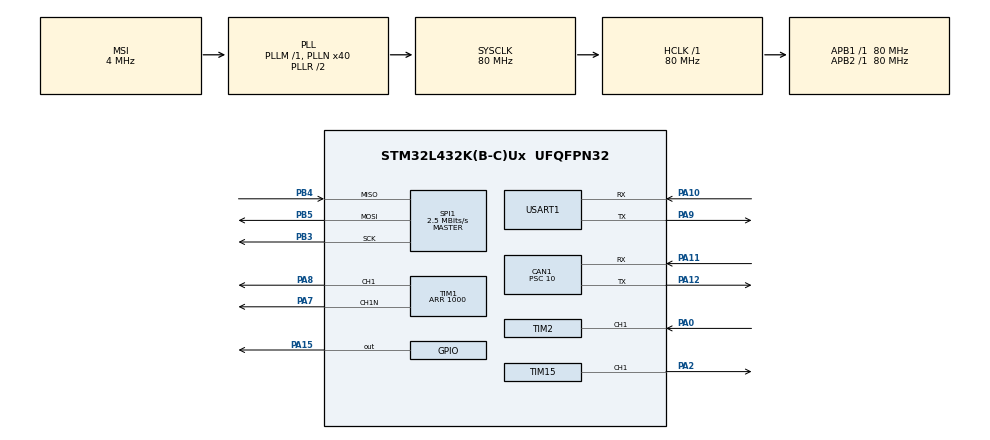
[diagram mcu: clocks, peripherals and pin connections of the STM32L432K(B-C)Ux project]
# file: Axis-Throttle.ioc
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CAN1.BS1=CAN_BS1_7TQ
CAN1.BS2=CAN_BS2_8TQ
CAN1.CalculateBaudRate=500000
CAN1.CalculateTimeBit=2000
CAN1.CalculateTimeQuantum=125.0
CAN1.Prescaler=10
CAN1.SJW=CAN_SJW_2TQ
CAN1.TXFP=ENABLE
Dma.Request0=USART1_RX
Dma.Request1=USART1_TX
Dma.USART1_RX.0.Direction=DMA_PERIPH_TO_MEMORY
Dma.USART1_RX.0.Instance=DMA1_Channel5
Dma.USART1_RX.0.MemDataAlignment=DMA_MDATAALIGN_BYTE
Dma.USART1_RX.0.MemInc=DMA_MINC_ENABLE
Dma.USART1_RX.0.Mode=DMA_NORMAL
Dma.USART1_RX.0.PeriphDataAlignment=DMA_PDATAALIGN_BYTE
Dma.USART1_RX.0.PeriphInc=DMA_PINC_DISABLE
Dma.USART1_RX.0.Priority=DMA_PRIORITY_LOW
Dma.USART1_TX.1.Direction=DMA_MEMORY_TO_PERIPH
Dma.USART1_TX.1.Instance=DMA1_Channel4
Dma.USART1_TX.1.MemDataAlignment=DMA_MDATAALIGN_BYTE
Dma.USART1_TX.1.MemInc=DMA_MINC_ENABLE
Dma.USART1_TX.1.Mode=DMA_NORMAL
Dma.USART1_TX.1.PeriphDataAlignment=DMA_PDATAALIGN_BYTE
Dma.USART1_TX.1.PeriphInc=DMA_PINC_DISABLE
Dma.USART1_TX.1.Priority=DMA_PRIORITY_LOW
FREERTOS.Tasks01=defaultTask,24,128,StartDefaultTask,Default,NULL,Dynamic,NULL,NULL
FREERTOS.configENABLE_FPU=1
FREERTOS.configGENERATE_RUN_TIME_STATS=1
FREERTOS.configTOTAL_HEAP_SIZE=40000
FREERTOS.configUSE_NEWLIB_REENTRANT=1
FREERTOS.configUSE_STATS_FORMATTING_FUNCTIONS=1
Mcu.Family=STM32L4
Mcu.Name=STM32L432K(B-C)Ux
Mcu.Package=UFQFPN32
NVIC.CAN1_RX0_IRQn=true\:5\:0\:false\:false\:false\:true\:true\:true\:true
NVIC.DMA1_Channel4_IRQn=true\:5\:0\:false\:false\:true\:true\:false\:true\:true
NVIC.DMA1_Channel5_IRQn=true\:5\:0\:false\:false\:true\:true\:false\:true\:true
NVIC.PriorityGroup=NVIC_PRIORITYGROUP_4
NVIC.USART1_IRQn=true\:5\:0\:false\:false\:true\:true\:true\:true\:true
PA0.Signal=S_TIM2_CH1
PA10.Mode=Asynchronous
PA10.Signal=USART1_RX
PA11.GPIO_PuPd=GPIO_PULLUP
PA11.Mode=CAN_Activate
PA11.Signal=CAN1_RX
PA12.Mode=CAN_Activate
PA12.Signal=CAN1_TX
PA13\ (JTMS-SWDIO).Mode=Serial_Wire
PA13\ (JTMS-SWDIO).Signal=SYS_JTMS-SWDIO
PA14\ (JTCK-SWCLK).Mode=Serial_Wire
PA14\ (JTCK-SWCLK).Signal=SYS_JTCK-SWCLK
PA15\ (JTDI).Signal=GPIO_Output
PA2.Signal=S_TIM15_CH1
PA7.Mode=PWM Generation1 CH1 CH1N
PA7.Signal=TIM1_CH1N
PA8.Signal=S_TIM1_CH1
PA9.Mode=Asynchronous
PA9.Signal=USART1_TX
PB3\ (JTDO-TRACESWO).Mode=Full_Duplex_Master
PB3\ (JTDO-TRACESWO).Signal=SPI1_SCK
PB4\ (NJTRST).Mode=Full_Duplex_Master
PB4\ (NJTRST).Signal=SPI1_MISO
PB5.Mode=Full_Duplex_Master
PB5.Signal=SPI1_MOSI
ProjectManager.HeapSize=0x200
ProjectManager.StackSize=0x400
ProjectManager.TargetToolchain=STM32CubeIDE
RCC.ADCFreq_Value=16000000
RCC.AHBFreq_Value=80000000
RCC.APB1Freq_Value=80000000
RCC.APB1TimFreq_Value=80000000
RCC.APB2Freq_Value=80000000
RCC.APB2TimFreq_Value=80000000
RCC.CortexFreq_Value=80000000
RCC.HCLKFreq_Value=80000000
RCC.HSE_VALUE=8000000
RCC.HSI48_VALUE=48000000
RCC.HSI_VALUE=16000000
RCC.LSE_VALUE=32768
RCC.MSI_VALUE=4000000
RCC.PLLN=40
RCC.SYSCLKFreq_VALUE=80000000
RCC.SYSCLKSource=RCC_SYSCLKSOURCE_PLLCLK
RCC.USBFreq_Value=16000000
RCC.VCOOutputFreq_Value=160000000
SH.S_TIM15_CH1.0=TIM15_CH1,PWM Generation1 CH1
SH.S_TIM1_CH1.0=TIM1_CH1,PWM Generation1 CH1 CH1N
SH.S_TIM2_CH1.0=TIM2_CH1,Input_Capture1_from_TI1
SH.S_TIM2_CH1.1=TIM2_CH1,TriggerSource_TI1FP1
SPI1.BaudRatePrescaler=SPI_BAUDRATEPRESCALER_32
SPI1.CLKPhase=SPI_PHASE_2EDGE
SPI1.CLKPolarity=SPI_POLARITY_HIGH
SPI1.CalculateBaudRate=2.5 MBits/s
SPI1.DataSize=SPI_DATASIZE_16BIT
SPI1.Direction=SPI_DIRECTION_2LINES
SPI1.Mode=SPI_MODE_MASTER
SPI1.TIMode=SPI_TIMODE_DISABLE
SPI1.VirtualType=VM_MASTER
TIM1.Channel-PWM\ Generation1\ CH1\ CH1N=TIM_CHANNEL_1
TIM1.Period=1000
TIM15.Channel-PWM\ Generation1\ CH1=TIM_CHANNEL_1
TIM15.Period=40000
TIM15.Prescaler=39
TIM2.Channel-Input_Capture1_from_TI1=TIM_CHANNEL_1
TIM2.Channel-Input_Capture2_from_TI1_63=TIM_CHANNEL_2
TIM2.ICPolarity_CH2=TIM_INPUTCHANNELPOLARITY_FALLING
TIM2.Prescaler=19
USART1.VirtualMode-Asynchronous=VM_ASYNC
VP_FREERTOS_VS_CMSIS_V2.Mode=CMSIS_V2
VP_TIM2_VS_ControllerModeReset.Mode=Reset Mode
VP_TIM2_VS_indirect_ch1.Mode=Input_Capture2_from_TI1_63
board=custom

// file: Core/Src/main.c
/* USER CODE BEGIN Header */
/**
  ******************************************************************************
  * @file           : main.c
  * @brief          : Main program body
  ******************************************************************************
  * @attention
  *
  * Copyright (c) 2024 STMicroelectronics.
  * All rights reserved.
  *
  * This software is licensed under terms that can be found in the LICENSE file
  * in the root directory of this software component.
  * If no LICENSE file comes with this software, it is provided AS-IS.
  *
  ******************************************************************************
  */
/* USER CODE END Header */
#include "main.h"
#include "cmsis_os.h"

/* USER CODE BEGIN Includes */
#include "Tasks/init.h"

/* USER CODE END Includes */

CAN_HandleTypeDef hcan1;

SPI_HandleTypeDef hspi1;

TIM_HandleTypeDef htim1;
TIM_HandleTypeDef htim2;
TIM_HandleTypeDef htim15;

UART_HandleTypeDef huart1;
DMA_HandleTypeDef hdma_usart1_rx;
DMA_HandleTypeDef hdma_usart1_tx;

/* Definitions for defaultTask */
osThreadId_t defaultTaskHandle;
const osThreadAttr_t defaultTask_attributes = {
  .name = "defaultTask",
  .stack_size = 128 * 4,
  .priority = (osPriority_t) osPriorityNormal,
};

void SystemClock_Config(void);
static void MX_GPIO_Init(void);
static void MX_DMA_Init(void);
static void MX_CAN1_Init(void);
static void MX_SPI1_Init(void);
static void MX_TIM1_Init(void);
static void MX_TIM2_Init(void);
static void MX_TIM15_Init(void);
static void MX_USART1_UART_Init(void);
void StartDefaultTask(void *argument);

int main(void)
{

  /* MCU Configuration--------------------------------------------------------*/

  /* Reset of all peripherals, Initializes the Flash interface and the Systick. */
  HAL_Init();

  /* Configure the system clock */
  SystemClock_Config();

  /* Initialize all configured peripherals */
  MX_GPIO_Init();
  MX_DMA_Init();
  MX_CAN1_Init();
  MX_SPI1_Init();
  MX_TIM1_Init();
  MX_TIM2_Init();
  MX_TIM15_Init();
  MX_USART1_UART_Init();

  /* Init scheduler */
  osKernelInitialize();

  /* Create the thread(s) */
  /* creation of defaultTask */
  defaultTaskHandle = osThreadNew(StartDefaultTask, NULL, &defaultTask_attributes);

  /* USER CODE BEGIN RTOS_THREADS */

  init_system();
  /* add threads, ... */
  /* USER CODE END RTOS_THREADS */

  /* Start scheduler */
  osKernelStart();

  /* We should never get here as control is now taken by the scheduler */
  /* Infinite loop */
  while (1)
  {

  }
}

void SystemClock_Config(void)
{
  RCC_OscInitTypeDef RCC_OscInitStruct = {0};
  RCC_ClkInitTypeDef RCC_ClkInitStruct = {0};

  /** Configure the main internal regulator output voltage
  */
  if (HAL_PWREx_ControlVoltageScaling(PWR_REGULATOR_VOLTAGE_SCALE1) != HAL_OK)
  {
    Error_Handler();
  }

  /** Initializes the RCC Oscillators according to the specified parameters
  * in the RCC_OscInitTypeDef structure.
  */
  RCC_OscInitStruct.OscillatorType = RCC_OSCILLATORTYPE_MSI;
  RCC_OscInitStruct.MSIState = RCC_MSI_ON;
  RCC_OscInitStruct.MSICalibrationValue = 0;
  RCC_OscInitStruct.MSIClockRange = RCC_MSIRANGE_6;
  RCC_OscInitStruct.PLL.PLLState = RCC_PLL_ON;
  RCC_OscInitStruct.PLL.PLLSource = RCC_PLLSOURCE_MSI;
  RCC_OscInitStruct.PLL.PLLM = 1;
  RCC_OscInitStruct.PLL.PLLN = 40;
  RCC_OscInitStruct.PLL.PLLP = RCC_PLLP_DIV7;
  RCC_OscInitStruct.PLL.PLLQ = RCC_PLLQ_DIV2;
  RCC_OscInitStruct.PLL.PLLR = RCC_PLLR_DIV2;
  if (HAL_RCC_OscConfig(&RCC_OscInitStruct) != HAL_OK)
  {
    Error_Handler();
  }

  /** Initializes the CPU, AHB and APB buses clocks
  */
  RCC_ClkInitStruct.ClockType = RCC_CLOCKTYPE_HCLK|RCC_CLOCKTYPE_SYSCLK
                              |RCC_CLOCKTYPE_PCLK1|RCC_CLOCKTYPE_PCLK2;
  RCC_ClkInitStruct.SYSCLKSource = RCC_SYSCLKSOURCE_PLLCLK;
  RCC_ClkInitStruct.AHBCLKDivider = RCC_SYSCLK_DIV1;
  RCC_ClkInitStruct.APB1CLKDivider = RCC_HCLK_DIV1;
  RCC_ClkInitStruct.APB2CLKDivider = RCC_HCLK_DIV1;

  if (HAL_RCC_ClockConfig(&RCC_ClkInitStruct, FLASH_LATENCY_4) != HAL_OK)
  {
    Error_Handler();
  }
}

static void MX_CAN1_Init(void)
{

  hcan1.Instance = CAN1;
  hcan1.Init.Prescaler = 10;
  hcan1.Init.Mode = CAN_MODE_NORMAL;
  hcan1.Init.SyncJumpWidth = CAN_SJW_2TQ;
  hcan1.Init.TimeSeg1 = CAN_BS1_7TQ;
  hcan1.Init.TimeSeg2 = CAN_BS2_8TQ;
  hcan1.Init.TimeTriggeredMode = DISABLE;
  hcan1.Init.AutoBusOff = DISABLE;
  hcan1.Init.AutoWakeUp = DISABLE;
  hcan1.Init.AutoRetransmission = DISABLE;
  hcan1.Init.ReceiveFifoLocked = DISABLE;
  hcan1.Init.TransmitFifoPriority = ENABLE;
  if (HAL_CAN_Init(&hcan1) != HAL_OK)
  {
    Error_Handler();
  }

}

static void MX_SPI1_Init(void)
{

  /* SPI1 parameter configuration*/
  hspi1.Instance = SPI1;
  hspi1.Init.Mode = SPI_MODE_MASTER;
  hspi1.Init.Direction = SPI_DIRECTION_2LINES;
  hspi1.Init.DataSize = SPI_DATASIZE_16BIT;
  hspi1.Init.CLKPolarity = SPI_POLARITY_HIGH;
  hspi1.Init.CLKPhase = SPI_PHASE_2EDGE;
  hspi1.Init.NSS = SPI_NSS_SOFT;
  hspi1.Init.BaudRatePrescaler = SPI_BAUDRATEPRESCALER_32;
  hspi1.Init.FirstBit = SPI_FIRSTBIT_MSB;
  hspi1.Init.TIMode = SPI_TIMODE_DISABLE;
  hspi1.Init.CRCCalculation = SPI_CRCCALCULATION_DISABLE;
  hspi1.Init.CRCPolynomial = 7;
  hspi1.Init.CRCLength = SPI_CRC_LENGTH_DATASIZE;
  hspi1.Init.NSSPMode = SPI_NSS_PULSE_DISABLE;
  if (HAL_SPI_Init(&hspi1) != HAL_OK)
  {
    Error_Handler();
  }

}

static void MX_TIM1_Init(void)
{

  TIM_MasterConfigTypeDef sMasterConfig = {0};
  TIM_OC_InitTypeDef sConfigOC = {0};
  TIM_BreakDeadTimeConfigTypeDef sBreakDeadTimeConfig = {0};

  htim1.Instance = TIM1;
  htim1.Init.Prescaler = 0;
  htim1.Init.CounterMode = TIM_COUNTERMODE_UP;
  htim1.Init.Period = 1000;
  htim1.Init.ClockDivision = TIM_CLOCKDIVISION_DIV1;
  htim1.Init.RepetitionCounter = 0;
  htim1.Init.AutoReloadPreload = TIM_AUTORELOAD_PRELOAD_DISABLE;
  if (HAL_TIM_PWM_Init(&htim1) != HAL_OK)
  {
    Error_Handler();
  }
  sMasterConfig.MasterOutputTrigger = TIM_TRGO_RESET;
  sMasterConfig.MasterOutputTrigger2 = TIM_TRGO2_RESET;
  sMasterConfig.MasterSlaveMode = TIM_MASTERSLAVEMODE_DISABLE;
  if (HAL_TIMEx_MasterConfigSynchronization(&htim1, &sMasterConfig) != HAL_OK)
  {
    Error_Handler();
  }
  sConfigOC.OCMode = TIM_OCMODE_PWM1;
  sConfigOC.Pulse = 0;
  sConfigOC.OCPolarity = TIM_OCPOLARITY_HIGH;
  sConfigOC.OCNPolarity = TIM_OCNPOLARITY_HIGH;
  sConfigOC.OCFastMode = TIM_OCFAST_DISABLE;
  sConfigOC.OCIdleState = TIM_OCIDLESTATE_RESET;
  sConfigOC.OCNIdleState = TIM_OCNIDLESTATE_RESET;
  if (HAL_TIM_PWM_ConfigChannel(&htim1, &sConfigOC, TIM_CHANNEL_1) != HAL_OK)
  {
    Error_Handler();
  }
  sBreakDeadTimeConfig.OffStateRunMode = TIM_OSSR_DISABLE;
  sBreakDeadTimeConfig.OffStateIDLEMode = TIM_OSSI_DISABLE;
  sBreakDeadTimeConfig.LockLevel = TIM_LOCKLEVEL_OFF;
  sBreakDeadTimeConfig.DeadTime = 0;
  sBreakDeadTimeConfig.BreakState = TIM_BREAK_DISABLE;
  sBreakDeadTimeConfig.BreakPolarity = TIM_BREAKPOLARITY_HIGH;
  sBreakDeadTimeConfig.BreakFilter = 0;
  sBreakDeadTimeConfig.Break2State = TIM_BREAK2_DISABLE;
  sBreakDeadTimeConfig.Break2Polarity = TIM_BREAK2POLARITY_HIGH;
  sBreakDeadTimeConfig.Break2Filter = 0;
  sBreakDeadTimeConfig.AutomaticOutput = TIM_AUTOMATICOUTPUT_DISABLE;
  if (HAL_TIMEx_ConfigBreakDeadTime(&htim1, &sBreakDeadTimeConfig) != HAL_OK)
  {
    Error_Handler();
  }
  HAL_TIM_MspPostInit(&htim1);

}

static void MX_TIM2_Init(void)
{

  TIM_SlaveConfigTypeDef sSlaveConfig = {0};
  TIM_MasterConfigTypeDef sMasterConfig = {0};
  TIM_IC_InitTypeDef sConfigIC = {0};

  htim2.Instance = TIM2;
  htim2.Init.Prescaler = 19;
  htim2.Init.CounterMode = TIM_COUNTERMODE_UP;
  htim2.Init.Period = 4294967295;
  htim2.Init.ClockDivision = TIM_CLOCKDIVISION_DIV1;
  htim2.Init.AutoReloadPreload = TIM_AUTORELOAD_PRELOAD_DISABLE;
  if (HAL_TIM_Base_Init(&htim2) != HAL_OK)
  {
    Error_Handler();
  }
  if (HAL_TIM_IC_Init(&htim2) != HAL_OK)
  {
    Error_Handler();
  }
  sSlaveConfig.SlaveMode = TIM_SLAVEMODE_RESET;
  sSlaveConfig.InputTrigger = TIM_TS_TI1FP1;
  sSlaveConfig.TriggerPolarity = TIM_INPUTCHANNELPOLARITY_RISING;
  sSlaveConfig.TriggerFilter = 0;
  if (HAL_TIM_SlaveConfigSynchro(&htim2, &sSlaveConfig) != HAL_OK)
  {
    Error_Handler();
  }
  sMasterConfig.MasterOutputTrigger = TIM_TRGO_RESET;
  sMasterConfig.MasterSlaveMode = TIM_MASTERSLAVEMODE_DISABLE;
  if (HAL_TIMEx_MasterConfigSynchronization(&htim2, &sMasterConfig) != HAL_OK)
  {
    Error_Handler();
  }
  sConfigIC.ICPolarity = TIM_INPUTCHANNELPOLARITY_RISING;
  sConfigIC.ICSelection = TIM_ICSELECTION_DIRECTTI;
  sConfigIC.ICPrescaler = TIM_ICPSC_DIV1;
  sConfigIC.ICFilter = 0;
  if (HAL_TIM_IC_ConfigChannel(&htim2, &sConfigIC, TIM_CHANNEL_1) != HAL_OK)
  {
    Error_Handler();
  }
  sConfigIC.ICPolarity = TIM_INPUTCHANNELPOLARITY_FALLING;
  sConfigIC.ICSelection = TIM_ICSELECTION_INDIRECTTI;
  if (HAL_TIM_IC_ConfigChannel(&htim2, &sConfigIC, TIM_CHANNEL_2) != HAL_OK)
  {
    Error_Handler();
  }

}

static void MX_TIM15_Init(void)
{

  TIM_MasterConfigTypeDef sMasterConfig = {0};
  TIM_OC_InitTypeDef sConfigOC = {0};
  TIM_BreakDeadTimeConfigTypeDef sBreakDeadTimeConfig = {0};

  htim15.Instance = TIM15;
  htim15.Init.Prescaler = 39;
  htim15.Init.CounterMode = TIM_COUNTERMODE_UP;
  htim15.Init.Period = 40000;
  htim15.Init.ClockDivision = TIM_CLOCKDIVISION_DIV1;
  htim15.Init.RepetitionCounter = 0;
  htim15.Init.AutoReloadPreload = TIM_AUTORELOAD_PRELOAD_DISABLE;
  if (HAL_TIM_PWM_Init(&htim15) != HAL_OK)
  {
    Error_Handler();
  }
  sMasterConfig.MasterOutputTrigger = TIM_TRGO_RESET;
  sMasterConfig.MasterSlaveMode = TIM_MASTERSLAVEMODE_DISABLE;
  if (HAL_TIMEx_MasterConfigSynchronization(&htim15, &sMasterConfig) != HAL_OK)
  {
    Error_Handler();
  }
  sConfigOC.OCMode = TIM_OCMODE_PWM1;
  sConfigOC.Pulse = 0;
  sConfigOC.OCPolarity = TIM_OCPOLARITY_HIGH;
  sConfigOC.OCNPolarity = TIM_OCNPOLARITY_HIGH;
  sConfigOC.OCFastMode = TIM_OCFAST_DISABLE;
  sConfigOC.OCIdleState = TIM_OCIDLESTATE_RESET;
  sConfigOC.OCNIdleState = TIM_OCNIDLESTATE_RESET;
  if (HAL_TIM_PWM_ConfigChannel(&htim15, &sConfigOC, TIM_CHANNEL_1) != HAL_OK)
  {
    Error_Handler();
  }
  sBreakDeadTimeConfig.OffStateRunMode = TIM_OSSR_DISABLE;
  sBreakDeadTimeConfig.OffStateIDLEMode = TIM_OSSI_DISABLE;
  sBreakDeadTimeConfig.LockLevel = TIM_LOCKLEVEL_OFF;
  sBreakDeadTimeConfig.DeadTime = 0;
  sBreakDeadTimeConfig.BreakState = TIM_BREAK_DISABLE;
  sBreakDeadTimeConfig.BreakPolarity = TIM_BREAKPOLARITY_HIGH;
  sBreakDeadTimeConfig.AutomaticOutput = TIM_AUTOMATICOUTPUT_DISABLE;
  if (HAL_TIMEx_ConfigBreakDeadTime(&htim15, &sBreakDeadTimeConfig) != HAL_OK)
  {
    Error_Handler();
  }
  HAL_TIM_MspPostInit(&htim15);

}

static void MX_USART1_UART_Init(void)
{

  huart1.Instance = USART1;
  huart1.Init.BaudRate = 115200;
  huart1.Init.WordLength = UART_WORDLENGTH_8B;
  huart1.Init.StopBits = UART_STOPBITS_1;
  huart1.Init.Parity = UART_PARITY_NONE;
  huart1.Init.Mode = UART_MODE_TX_RX;
  huart1.Init.HwFlowCtl = UART_HWCONTROL_NONE;
  huart1.Init.OverSampling = UART_OVERSAMPLING_16;
  huart1.Init.OneBitSampling = UART_ONE_BIT_SAMPLE_DISABLE;
  huart1.AdvancedInit.AdvFeatureInit = UART_ADVFEATURE_NO_INIT;
  if (HAL_UART_Init(&huart1) != HAL_OK)
  {
    Error_Handler();
  }

}

static void MX_DMA_Init(void)
{

  /* DMA controller clock enable */
  __HAL_RCC_DMA1_CLK_ENABLE();

  /* DMA interrupt init */
  /* DMA1_Channel4_IRQn interrupt configuration */
  HAL_NVIC_SetPriority(DMA1_Channel4_IRQn, 5, 0);
  HAL_NVIC_EnableIRQ(DMA1_Channel4_IRQn);
  /* DMA1_Channel5_IRQn interrupt configuration */
  HAL_NVIC_SetPriority(DMA1_Channel5_IRQn, 5, 0);
  HAL_NVIC_EnableIRQ(DMA1_Channel5_IRQn);

}

static void MX_GPIO_Init(void)
{
  GPIO_InitTypeDef GPIO_InitStruct = {0};

  /* GPIO Ports Clock Enable */
  __HAL_RCC_GPIOA_CLK_ENABLE();
  __HAL_RCC_GPIOB_CLK_ENABLE();

  /*Configure GPIO pin Output Level */
  HAL_GPIO_WritePin(GPIOA, GPIO_PIN_15, GPIO_PIN_RESET);

  /*Configure GPIO pin : PA15 */
  GPIO_InitStruct.Pin = GPIO_PIN_15;
  GPIO_InitStruct.Mode = GPIO_MODE_OUTPUT_PP;
  GPIO_InitStruct.Pull = GPIO_NOPULL;
  GPIO_InitStruct.Speed = GPIO_SPEED_FREQ_LOW;
  HAL_GPIO_Init(GPIOA, &GPIO_InitStruct);

}

void StartDefaultTask(void *argument)
{
  for(;;)
  {
    osDelay(1);
  }
}

void Error_Handler(void)
{
  __disable_irq();
  while (1)
  {
  }
}

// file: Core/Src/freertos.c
/* USER CODE BEGIN Header */
/**
  ******************************************************************************
  * File Name          : freertos.c
  * Description        : Code for freertos applications
  ******************************************************************************
  * @attention
  *
  * Copyright (c) 2024 STMicroelectronics.
  * All rights reserved.
  *
  * This software is licensed under terms that can be found in the LICENSE file
  * in the root directory of this software component.
  * If no LICENSE file comes with this software, it is provided AS-IS.
  *
  ******************************************************************************
  */
/* USER CODE END Header */

#include "FreeRTOS.h"
#include "task.h"
#include "main.h"

/* Hook prototypes */
void configureTimerForRunTimeStats(void);
unsigned long getRunTimeCounterValue(void);

/* USER CODE BEGIN 1 */
/* Functions needed when configGENERATE_RUN_TIME_STATS is on */
__weak void configureTimerForRunTimeStats(void)
{

}

__weak unsigned long getRunTimeCounterValue(void)
{
return 0;
}
/* USER CODE END 1 */
